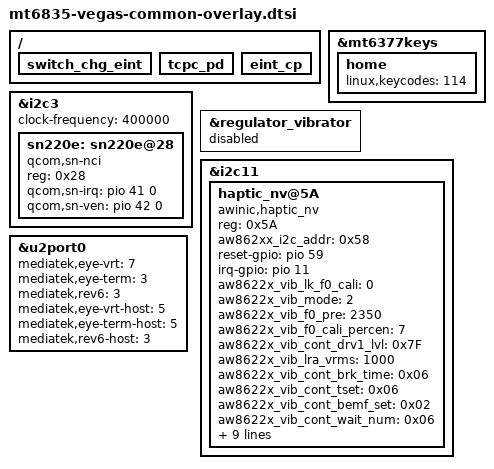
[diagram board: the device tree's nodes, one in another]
/* Copyright (c) 2023, Motorola Mobility Inc. All rights reserved.
 *
 * This program is free software; you can redistribute it and/or modify
 * it under the terms of the GNU General Public License version 2 and
 * only version 2 as published by the Free Software Foundation.
 *
 * This program is distributed in the hope that it will be useful,
 * but WITHOUT ANY WARRANTY; without even the implied warranty of
 * MERCHANTABILITY or FITNESS FOR A PARTICULAR PURPOSE.  See the
 * GNU General Public License for more details.
 */

#include "mediatek/mt6835-moto-common-overlay.dtsi"
#include "mediatek/aw37004.dtsi"
#include "mediatek/vegas-display.dtsi"
#include "mediatek/vegas-touch.dtsi"
#include "mediatek/vegas-fps.dtsi"
#include "mediatek/mt6835-moto-memory.dtsi"
#include "mediatek/vegas-charger.dtsi"
#include "mediatek/vegas-sensor.dtsi"
#include "mediatek/vegas-msdc.dtsi"
#include "mediatek/vegas-audio.dtsi"
#include "mediatek/vegas-thermal.dtsi"
#include "mediatek/cust_mt6835_camera_6377_v4l2.dtsi"
/ {
switch_chg_eint: switch_chg_eint {
	};
tcpc_pd: tcpc_pd {
	};
eint_cp: eint_cp {
	};
};

&mt6377keys {
	home {
		linux,keycodes = <114>;
	};
};

&i2c3 {
        clock-frequency = <400000>;

        sn220e: sn220e@28 {
                compatible = "qcom,sn-nci";
                reg = <0x28>;
                qcom,sn-irq = <&pio 41 0>;
                qcom,sn-ven = <&pio 42  0>;
                status = "okay";
        };
};

&swtp {
	swtp: swtp {
		compatible = "mediatek, swtp-eint";
		interrupt-parent = <&pio>;
		interrupts = <36 IRQ_TYPE_LEVEL_HIGH 36 0>;
		deb-gpios = <&pio 36 0>;
		debounce = <512>;
		status = "okay";
	};

	swtp_1: swtp_1 {
		compatible = "mediatek, swtp1-eint";
		interrupt-parent = <&pio>;
		interrupts = <37 IRQ_TYPE_LEVEL_HIGH 37 0>;
		deb-gpios = <&pio 37 0>;
		debounce = <512>;
		status = "okay";
	};

	swtp_2: swtp_2 {
		compatible = "mediatek, swtp2-eint";
		interrupt-parent = <&pio>;
		interrupts = <38 IRQ_TYPE_LEVEL_HIGH 38 0>;
		deb-gpios = <&pio 38 0>;
		debounce = <512>;
		status = "okay";
	};

	swtp_3: swtp_3 {
		compatible = "mediatek, swtp3-eint";
		interrupt-parent = <&pio>;
		interrupts = <39 IRQ_TYPE_LEVEL_HIGH 39 0>;
		deb-gpios = <&pio 39 0>;
		debounce = <512>;
		status = "okay";
	};
};

&regulator_vibrator {
	status = "disabled";
};

&i2c11 {
	haptic_nv@5A{
		compatible = "awinic,haptic_nv";
		reg = < 0x5A >;
		aw862xx_i2c_addr = < 0x58 >;
		reset-gpio = <&pio 59 0>;
		irq-gpio = <&pio 11 0>;
		aw8622x_vib_lk_f0_cali = < 0 >;
		aw8622x_vib_mode = < 2 >; /* mode: RAM -> 2; CONT -> 3 */
		aw8622x_vib_f0_pre = < 2350 >;
		aw8622x_vib_f0_cali_percen = < 7 >;
		aw8622x_vib_cont_drv1_lvl = < 0x7F >;
		aw8622x_vib_lra_vrms = < 1000 >; /* Motor rated voltage, mV */
		aw8622x_vib_cont_brk_time = < 0x06 >;
		aw8622x_vib_cont_tset = < 0x06 >;
		aw8622x_vib_cont_bemf_set = < 0x02 >;
		aw8622x_vib_cont_wait_num = < 0x06 >;
		aw8622x_vib_cont_brk_gain = < 0x08 >;
		aw8622x_vib_cont_drv1_time = < 0x04 >;
		aw8622x_vib_cont_drv2_time = < 0x14 >;
		aw8622x_vib_cont_track_margin = < 0x0F >;
		aw8622x_vib_sine_array = < 0x05 0xB2 0xFF 0xEF >; /* SIN_H SIN_L COS_H COS_L */
		aw8622x_vib_d2s_gain = < 0x05 >;
		aw8622x_vib_trig_config = < 0 0 0 1 0 2 0
					    0 0 0 1 0 2 0
					    0 0 0 1 0 2 0 >;
		aw8622x_vib_duration_time = < 34 67 100 >;
		status = "okay";
	};
};

&u2port0 {
	mediatek,eye-vrt = <7>;
	mediatek,eye-term = <3>;
	mediatek,rev6 = <3>;
	mediatek,eye-vrt-host = <5>;
	mediatek,eye-term-host = <5>;
	mediatek,rev6-host = <3>;
};
